AUTOSAR XML (schema 00046)
package /ComponentTypes
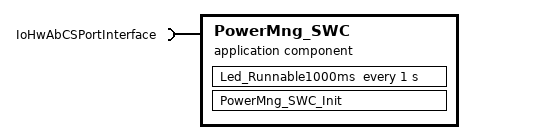
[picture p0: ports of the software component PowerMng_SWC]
  application sw component type PowerMng_SWC
    require port IoHwAbCSPortInterface: client-com-spec=IoHwAb_Dio_WriteChannel, required-interface=IoHwAbCSPortInterface
    behavior PowerMng_SWC_InternalBehavior
      timing event TMT_Led_Runnable1000ms: start-on-event=Led_Runnable1000ms, period=1
      init event PowerMng_SWC_InitEvent: start-on-event=PowerMng_SWC_Init
      runnable Led_Runnable1000ms
        sync call SC_IoHwAbCSPortInterface_IoHwAb_Dio_WriteChannel: operation=IoHwAbCSPortInterface.IoHwAb_Dio_WriteChannel
      runnable PowerMng_SWC_Init
  swc implementation PowerMng_SWC_Implementation: behavior=PowerMng_SWC_InternalBehavior
